AUTOSAR XML (schema 4-2-2)
package /IoHwAb_ICU
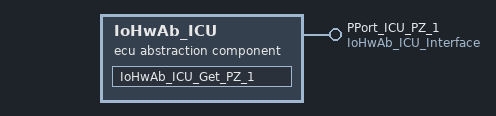
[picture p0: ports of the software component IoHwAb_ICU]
  ecu abstraction sw component type IoHwAb_ICU
    provide port PPort_ICU_PZ_1: provided-interface=IoHwAb_ICU_Interface
    behavior IB_IoHwAb_ICU
      operation invoked event OperationInvokedEvent_0: start-on-event=IoHwAb_ICU_Get_PZ_1, operation=PPort_ICU_PZ_1.IoHwAb_ICU_Get
      runnable IoHwAb_ICU_Get_PZ_1: symbol=IoHwAb_ICU_Get_PZ_1_func
